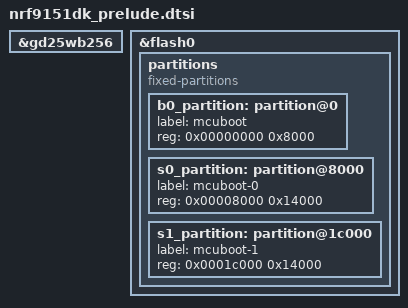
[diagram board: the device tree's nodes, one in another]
/*
 * Copyright (c) 2026 Nordic Semiconductor ASA
 *
 * SPDX-License-Identifier: LicenseRef-Nordic-5-Clause
 *
 * nRF9151 DK prelude — include before att_flash_partitions.dtsi.
 * Aliases gd25wb256 as flash_ext; adds b0/s0/s1 partitions on internal flash.
 */

flash_ext: &gd25wb256 {
	status = "okay";
};

/delete-node/ &boot_partition;
/delete-node/ &tfm_ps_partition;
/delete-node/ &tfm_its_partition;
/delete-node/ &tfm_otp_partition;

&flash0 {
	partitions {
		compatible = "fixed-partitions";
		#address-cells = <1>;
		#size-cells = <1>;

		b0_partition: partition@0 {
			label = "mcuboot";
			reg = <0x00000000 0x8000>;
		};

		s0_partition: partition@8000 {
			label = "mcuboot-0";
			reg = <0x00008000 0x14000>;
		};

		s1_partition: partition@1c000 {
			label = "mcuboot-1";
			reg = <0x0001c000 0x14000>;
		};
	};
};
